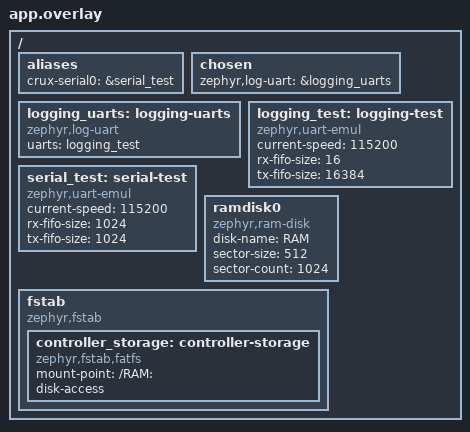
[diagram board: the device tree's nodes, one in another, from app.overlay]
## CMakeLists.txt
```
# SPDX-License-Identifier: Apache-2.0

# The base composition of the controller framework on native_sim, built as a product builds it:
# the framework is the Zephyr module of this repository, turned on by CONFIG_CRUX_CONTROLLER_FRAMEWORK
# in prj.conf. This file names no source and no include directory of this repository. It links the
# interface target of the module and calls the module's image function, which adds the route table
# and the packaged page of web management to the target app, as the base image does.

cmake_minimum_required(VERSION 3.20.0)
find_package(Zephyr REQUIRED HINTS $ENV{ZEPHYR_BASE})
project(controller_framework_base_native_sim LANGUAGES C)

if(NOT CONFIG_BOARD_NATIVE_SIM OR NOT CONFIG_FAKE_ENTROPY_NATIVE_SIM)
    message(FATAL_ERROR "This scenario is restricted to native_sim: its entropy source is a test source")
endif()
if(NOT CONFIG_CRUX_CONTROLLER_FRAMEWORK OR NOT CONFIG_CRUX_CONTROLLER_FRAMEWORK_MANAGEMENT
   OR NOT CONFIG_CRUX_CONTROLLER_FRAMEWORK_TIME_SYNC)
    message(FATAL_ERROR "The base scenario needs the framework with web management and time synchronisation")
endif()

target_sources(app PRIVATE src/test_base.c)
target_link_libraries(app PRIVATE controller::framework)
controller_framework_image()
```

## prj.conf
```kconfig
# The base composition of the controller framework on native_sim, as a product would build it:
# the framework comes from the module (zephyr/module.yml) and one Kconfig symbol, and the test
# reaches it through <controller/framework.h> only. The values below are those of the
# management scenario (tests/native_sim_mbed/management/prj.conf), with the framework, the SNTP
# library and a time server on the loopback address added. No SNTP server answers there, so the
# time synchronisation thread starts and its queries fail; the scenario checks that it started.
# The Crux serial console runs on an emulated UART of its own (app.overlay), into which the
# scenario types the first-account setup and a login.
CONFIG_CRUX_CONTROLLER_FRAMEWORK=y
CONFIG_SNTP=y
CONFIG_CRUX_CONTROLLER_TIME_SERVER="127.0.0.1"

# Health supervision as in the base image (app/conf/base.conf), in its production watchdog
# configuration (criterion 19): no task watchdog hardware fallback, no start without a watchdog, no
# fault injection. native_sim has no watchdog behind the alias crux-watchdog0 here, so the watchdog
# is not armed and the controller is degraded. There is no retained region either, so the boot
# counter lives in RAM. The stable period is longer than the scenario, so the counter is not cleared.
CONFIG_TASK_WDT=y
CONFIG_TASK_WDT_HW_FALLBACK=n
CONFIG_CRUX_REBOOT=y
CONFIG_CRUX_CONTROLLER_STABLE_PERIOD_S=3600

CONFIG_CRUX_SERIAL=y
CONFIG_CRUX_CLI=y
CONFIG_CRUX_CLI_CONSOLE=y
CONFIG_CRUX_CLI_CONSOLE_PRIORITY=11
CONFIG_UART_INTERRUPT_DRIVEN=y
CONFIG_UART_USE_RUNTIME_CONFIGURE=y

CONFIG_ZTEST=y
CONFIG_ZTEST_VERIFY_RUN_ALL=n
CONFIG_STD_C17=y
CONFIG_EMUL=y
CONFIG_UART_EMUL=y
CONFIG_IRQ_OFFLOAD=y
# The web adapter refuses the external libc of native_sim; the management scenario runs on picolibc.
CONFIG_PICOLIBC=y
# One thread of the test runs the start sequence (key generation, signing, the format of the RAM
# disk) and the TLS client. Not measured.
CONFIG_MAIN_STACK_SIZE=32768
CONFIG_ZTEST_STACK_SIZE=32768
CONFIG_HEAP_MEM_POOL_SIZE=32768

# The Mbed TLS profile of app/conf/management.conf, as a copy: this scenario has no Kconfig of the product,
# as in the management scenario. The heap is larger than the product's 120,000 bytes,
# because the TLS client of the test runs in the same process and takes up to one more connection
# and its own handshake. The product declares 120,000 bytes for three server connections of 34,912
# bytes, a handshake of 3,576 bytes and the other PSA users, and 180,000 leaves about 25,000 bytes
# over the worst concurrent case that this process can reach. A paper figure, not measured.
CONFIG_MBEDTLS=y
CONFIG_MBEDTLS_PSA_CRYPTO_C=y
CONFIG_PSA_CRYPTO_PROVIDER_MBEDTLS=y
CONFIG_MBEDTLS_ENABLE_HEAP=y
CONFIG_MBEDTLS_HEAP_SIZE=180000
CONFIG_MBEDTLS_SSL_IN_CONTENT_LEN=16384
CONFIG_MBEDTLS_SSL_OUT_CONTENT_LEN=16384
CONFIG_MBEDTLS_SSL_PROTO_TLS1_2=y
CONFIG_MBEDTLS_SSL_PROTO_TLS1_3=y
CONFIG_MBEDTLS_SSL_TLS1_3_KEY_EXCHANGE_MODE_EPHEMERAL_ENABLED=y
CONFIG_MBEDTLS_KEY_EXCHANGE_ECDHE_ECDSA_ENABLED=y
CONFIG_MBEDTLS_CIPHERSUITE_TLS_ECDHE_ECDSA_WITH_AES_128_GCM_SHA256=y
CONFIG_MBEDTLS_CIPHERSUITE_TLS1_3_AES_128_GCM_SHA256=y
CONFIG_PSA_WANT_ALG_SHA_256=y
CONFIG_PSA_WANT_ECC_SECP_R1_256=y
CONFIG_PSA_WANT_ALG_ECDSA=y
CONFIG_PSA_WANT_ALG_ECDH=y
CONFIG_PSA_WANT_ALG_GCM=y
CONFIG_PSA_WANT_KEY_TYPE_AES=y
CONFIG_PSA_WANT_ALG_HMAC=y
CONFIG_PSA_WANT_KEY_TYPE_HMAC=y
CONFIG_PSA_WANT_ALG_HKDF=y
CONFIG_PSA_WANT_ALG_PBKDF2_HMAC=y
CONFIG_PSA_WANT_ALG_TLS12_PRF=y
CONFIG_PSA_WANT_KEY_TYPE_ECC_PUBLIC_KEY=y
CONFIG_PSA_WANT_KEY_TYPE_ECC_KEY_PAIR_IMPORT=y
CONFIG_PSA_WANT_KEY_TYPE_ECC_KEY_PAIR_EXPORT=y
CONFIG_PSA_WANT_KEY_TYPE_ECC_KEY_PAIR_GENERATE=y
CONFIG_PSA_WANT_KEY_TYPE_ECC_KEY_PAIR_DERIVE=y
CONFIG_MBEDTLS_PK_WRITE_C=y
CONFIG_CRUX_PSA_THREADING=y

# The Crux services, as in app/conf/management.conf. The module selects Thread, Sync and Time for them.
CONFIG_CRUX_ACCESS=y
CONFIG_CRUX_CONFIG_SERVICE=y
CONFIG_CRUX_MGMT_STATUS=y
CONFIG_CRUX_TLS_CERTIFICATE=y
CONFIG_CRUX_WEB=y
CONFIG_CRUX_WEB_SESSION=y
CONFIG_CRUX_WEB_MANAGEMENT=y
CONFIG_CRUX_SYSTEM=y
CONFIG_CRUX_NETIF=y
CONFIG_WATCHDOG=y
CONFIG_HWINFO=y
CONFIG_REBOOT=y

# The listener binds the loopback address, and the TLS client of the test is in the same process. The
# listener opens on Zephyr's own thread, so the client retries its connect.
CONFIG_CRUX_WEB_PORT=443
CONFIG_CRUX_WEB_BIND_ADDRESS="127.0.0.1"
CONFIG_CRUX_WEB_BACKLOG=4
CONFIG_HTTP_SERVER_MAX_CLIENTS=3
CONFIG_HTTP_SERVER_STACK_SIZE=16384
CONFIG_CRUX_WEB_SESSION_WORKER_PRIORITY=11
CONFIG_CRUX_WEB_MANAGEMENT_WORKER_PRIORITY=11
CONFIG_CRUX_SECURITY_EVENT_DRAIN_PRIORITY=11

# The simulator's fake entropy source: test-only, so nothing made here is a secret.
CONFIG_ENTROPY_GENERATOR=y

# Crux File on a RAM disk with the simulator provider, and the formatting service that the zone
# uses when the blank disk does not mount.
CONFIG_FILE_SYSTEM=y
CONFIG_FILE_SYSTEM_MKFS=y
CONFIG_FAT_FILESYSTEM_ELM=y
CONFIG_FS_FATFS_LFN=y
CONFIG_FS_FATFS_LFN_MODE_STACK=y
CONFIG_FS_FATFS_MAX_LFN=127
CONFIG_FS_FATFS_MOUNT_MKFS=n
CONFIG_FS_FATFS_REENTRANT=y
CONFIG_FS_FATFS_NUM_FILES=6
CONFIG_DISK_DRIVERS=y
CONFIG_DISK_DRIVER_RAM=y
CONFIG_CRUX_FILE_FATFS_SIMULATOR=y

# The network: Zephyr's loopback interface, TCP and the TLS socket layer, with no host network.
CONFIG_NETWORKING=y
CONFIG_NET_IPV4=y
CONFIG_NET_IPV6=n
CONFIG_NET_TCP=y
CONFIG_NET_UDP=y
CONFIG_NET_SOCKETS=y
CONFIG_NET_DRIVERS=y
CONFIG_NET_LOOPBACK=y
CONFIG_NET_SOCKETS_SOCKOPT_TLS=y
CONFIG_TLS_CREDENTIALS=y
CONFIG_TLS_MAX_CREDENTIALS_NUMBER=4
CONFIG_NET_SOCKETS_TLS_MAX_CONTEXTS=6
CONFIG_ZVFS_OPEN_MAX=48
CONFIG_ZVFS_POLL_MAX=24
CONFIG_ZVFS_EVENTFD=y
CONFIG_NET_MAX_CONTEXTS=32
CONFIG_NET_MAX_CONN=32
CONFIG_NET_PKT_RX_COUNT=64
CONFIG_NET_PKT_TX_COUNT=64
CONFIG_NET_BUF_RX_COUNT=256
CONFIG_NET_BUF_TX_COUNT=256

# Crux Logging writes to an emulated UART, so that the test can read what it wrote.
CONFIG_CRUX_LOGGING=y
CONFIG_SERIAL=y
CONFIG_LOG=y
CONFIG_LOG_MODE_DEFERRED=y
CONFIG_LOG_MODE_OVERFLOW=n
CONFIG_LOG_BLOCK_IN_THREAD=n
CONFIG_LOG_PROCESS_THREAD=y
CONFIG_LOG_PROCESS_THREAD_STACK_SIZE=2048
CONFIG_LOG_PROCESS_THREAD_CUSTOM_PRIORITY=y
CONFIG_LOG_PROCESS_THREAD_PRIORITY=14
CONFIG_LOG_BUFFER_SIZE=8192
CONFIG_LOG_MAX_LEVEL=4
CONFIG_LOG_DEFAULT_LEVEL=0
CONFIG_LOG_RUNTIME_FILTERING=n
CONFIG_LOG_BACKEND_UART=y
CONFIG_LOG_BACKEND_NATIVE_POSIX=n
CONFIG_LOG_BACKEND_UART_ASYNC=n
CONFIG_LOG_PRINTK=n
CONFIG_SHELL_LOG_BACKEND=n
CONFIG_LOG_BACKEND_SHOW_LEVEL=y
CONFIG_LOG_BACKEND_CRLF_NONE=n
CONFIG_THREAD_MONITOR=y
CONFIG_THREAD_NAME=y
# An image with Crux management must not enable the Zephyr shell.
CONFIG_SHELL=n
```

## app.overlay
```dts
/* The devicetree of the management scenario (tests/native_sim_mbed/management/app.overlay).
 * Crux Logging writes to an emulated UART here, so that the test can read what it wrote. The RAM
 * disk and the fstab entry are the ones that boards/management.overlay declares for the board, with the
 * same names, because the composition zone looks up the entry controller_storage. The disk is
 * blank at every start: the zone formats it. The Crux serial console owns a second emulated UART
 * through the alias crux-serial0: the test types into its receive side and reads its transmit
 * side. */
/ {
    aliases { crux-serial0 = &serial_test; };
    chosen { zephyr,log-uart = &logging_uarts; };
    logging_uarts: logging-uarts {
        compatible = "zephyr,log-uart";
        uarts = <&logging_test>;
    };
    logging_test: logging-test {
        compatible = "zephyr,uart-emul";
        current-speed = <115200>;
        rx-fifo-size = <16>;
        tx-fifo-size = <16384>;
        status = "okay";
    };
    serial_test: serial-test {
        compatible = "zephyr,uart-emul";
        current-speed = <115200>;
        rx-fifo-size = <1024>;
        tx-fifo-size = <1024>;
        status = "okay";
    };

    ramdisk0 {
        compatible = "zephyr,ram-disk";
        disk-name = "RAM";
        sector-size = <512>;
        sector-count = <1024>;
    };

    fstab {
        compatible = "zephyr,fstab";
        controller_storage: controller-storage {
            compatible = "zephyr,fstab,fatfs";
            mount-point = "/RAM:";
            disk-access;
        };
    };
};
```

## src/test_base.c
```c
/* SPDX-License-Identifier: Apache-2.0 */

/* The base composition of the controller framework on native_sim, built as a product builds it:
 * the framework comes from the Zephyr module of this repository and the Kconfig symbol
 * CONFIG_CRUX_CONTROLLER_FRAMEWORK, the test calls the start function of
 * <controller/framework.h>, and the CMake file of this scenario names no source or include
 * directory of this repository. It runs the real Crux services, Zephyr's HTTP server with Mbed TLS
 * and the SNTP library over the loopback interface, and the Crux serial console on an emulated
 * UART, into which the test types as a person types at a terminal.
 *
 * One image runs the cases in order, because the start function runs once per program.
 *
 * Health supervision runs in its production watchdog configuration with no watchdog behind the
 * alias crux-watchdog0, so the watchdog is not armed and the controller is degraded (criterion 19,
 * base image part), and the scenario shows the start order of criterion 6: the reset cause read
 * once and cleared, the supervisor step before the step that mounts the volume, the captured copy
 * in the status service, and the end of startup supervision in step 12 with no application.
 *
 * What this scenario cannot show: anything on a board, the Ethernet interface, the board's UART for
 * the console, the RT1060 entropy source (the entropy here is the simulator's test source), a TLS
 * session or an HTTPS login (the management scenario shows those for the same start sequence), an
 * account that outlives a restart (the disk is a RAM disk), a synchronised clock (no SNTP server
 * answers on the loopback address), an armed watchdog, a retained region or a reset (the scenarios
 * recovery and no_watchdog show those), stack use or timing. */

#include <errno.h>
#include <stdbool.h>
#include <stddef.h>
#include <stdint.h>
#include <string.h>

#include <controller/framework.h>
#include <zephyr/device.h>
#include <zephyr/drivers/serial/uart_emul.h>
#include <zephyr/kernel.h>
#include <zephyr/logging/log_ctrl.h>
#include <zephyr/net/socket.h>
#include <zephyr/ztest.h>

#define LOG_UART DEVICE_DT_GET(DT_NODELABEL(logging_test))
#define CONSOLE_UART DEVICE_DT_GET(DT_NODELABEL(serial_test))
/* The listener opens on Zephyr's own thread, so the first connects can be refused. */
#define CONNECT_ATTEMPTS 40
#define CONNECT_RETRY_MS 100
/* The console polls in steps of this length, up to the number of attempts. */
#define CONSOLE_POLL_MS 10
#define CONSOLE_ATTEMPTS 1000

#define FIRST_USER "operator"
#define FIRST_PASSWORD "base image test password"
#define WRONG_PASSWORD "this is the wrong password"
/* The first eight bytes of each, which no prompt or reply of the console contains. */
#define FIRST_PASSWORD_START "base ima"
#define WRONG_PASSWORD_START "this is "

static char log_text[16384];
static size_t log_length;

/* Everything that Crux Logging wrote since the last call, appended to what was read before. */
static const char *drain_log(void)
{
    log_flush();
    log_length += uart_emul_get_tx_data(LOG_UART, (uint8_t *)log_text + log_length,
                                        sizeof log_text - 1u - log_length);
    log_text[log_length] = '\0';
    return log_text;
}

/* What the console has written and no expectation has consumed yet. */
static char console_text[8192];
static size_t console_length;

static void console_drain(void)
{
    uint8_t chunk[64];
    uint32_t got;

    while ((got = uart_emul_get_tx_data(CONSOLE_UART, chunk, sizeof chunk)) > 0u) {
        zassert_true(console_length + got < sizeof console_text, "the console wrote too much");
        memcpy(&console_text[console_length], chunk, got);
        console_length += got;
        console_text[console_length] = '\0';
        /* A password is read without echo: neither a whole one nor its first bytes come back. */
        zassert_is_null(strstr(console_text, FIRST_PASSWORD_START), "a password was echoed");
        zassert_is_null(strstr(console_text, WRONG_PASSWORD_START), "a password was echoed");
    }
}

/* Wait for the console to write text, then drop everything up to and including it. With first,
 * nothing may come before it. */
static void console_expect(const char *text, bool first)
{
    const size_t length = strlen(text);

    for (int attempt = 0; attempt < CONSOLE_ATTEMPTS; attempt++) {
        console_drain();
        const char *found = strstr(console_text, text);

        if (first && console_length >= length) {
            zassert_equal(strncmp(console_text, text, length), 0, "first output: %s", console_text);
        }
        if (found != NULL) {
            const size_t consumed = (size_t)(found - console_text) + length;

            memmove(console_text, &console_text[consumed], console_length - consumed + 1u);
            console_length -= consumed;
            return;
        }
        k_msleep(CONSOLE_POLL_MS);
    }
    zassert_unreachable("the console did not write \"%s\"; it wrote \"%s\"", text, console_text);
}

/* Type a line as a terminal does: the bytes and a carriage return. */
static void console_type(const char *text)
{
    char line[96];
    const size_t length = strlen(text);

    zassert_true(length + 1u < sizeof line);
    memcpy(line, text, length);
    line[length] = '\r';
    zassert_equal(uart_emul_put_rx_data(CONSOLE_UART, (const uint8_t *)line, length + 1u),
                  length + 1u);
}

ZTEST_SUITE(base, NULL, NULL, NULL, NULL, NULL);

ZTEST(base, test_01_start_runs_every_phase)
{
    zassert_equal(controller_framework_start(NULL), CONTROLLER_FRAMEWORK_OK);
    const char *log = drain_log();

    zassert_not_null(strstr(log, "phase clock ok"), "%s", log);
    zassert_not_null(strstr(log, "phase supervisor ok"), "%s", log);
    zassert_not_null(strstr(log, "phase storage access ok"), "%s", log);
    zassert_not_null(strstr(log, "phase web management ok"), "%s", log);
    zassert_not_null(strstr(log, "phase command line ok"), "%s", log);
    zassert_not_null(strstr(log, "phase time synchronisation ok"), "%s", log);
    zassert_not_null(strstr(log, "phase application ok"), "%s", log);
    /* With no application, the application's own steps (init and the start prerequisites) are
     * left out and not counted. */
    zassert_not_null(strstr(log, "phase app init left out: no application"), "%s", log);
    zassert_not_null(strstr(log, "phase start prerequisites left out: no application"), "%s", log);
    zassert_not_null(strstr(log, "startup done phases=7 failed=0"), "%s", log);
}

ZTEST(base, test_02_phases_run_in_order)
{
    const char *log = drain_log();
    const char *clock = strstr(log, "phase clock ok");
    const char *supervisor = strstr(log, "phase supervisor ok");
    const char *storage = strstr(log, "phase storage access ok");
    const char *web = strstr(log, "phase web management ok");
    const char *cli = strstr(log, "phase command line ok");
    const char *time = strstr(log, "phase time synchronisation ok");
    const char *application = strstr(log, "phase application ok");

    zassert_true(clock != NULL && supervisor != NULL && storage != NULL && web != NULL &&
                     cli != NULL && time != NULL && application != NULL,
                 "%s", log);
    zassert_true(clock < supervisor && supervisor < storage && storage < web && web < cli &&
                     cli < time && time < application,
                 "%s", log);
    zassert_not_null(strstr(log, "https management started on 127.0.0.1 port 443"), "%s", log);
    zassert_not_null(strstr(log, "serial command line started on crux-serial0"), "%s", log);
}

ZTEST(base, test_03_a_second_start_is_refused)
{
    zassert_equal(controller_framework_start(NULL), CONTROLLER_FRAMEWORK_ERR_ALREADY_STARTED);
}

ZTEST(base, test_04_the_listener_accepts_a_connection)
{
    struct net_sockaddr_in address = {
        .sin_family = NET_AF_INET,
        .sin_port = net_htons(443),
    };
    int last_errno = 0;
    bool connected = false;

    zassert_equal(zsock_inet_pton(NET_AF_INET, "127.0.0.1", &address.sin_addr), 1);
    for (int attempt = 0; attempt < CONNECT_ATTEMPTS && !connected; attempt++) {
        const int sock = zsock_socket(NET_AF_INET, NET_SOCK_STREAM, NET_IPPROTO_TCP);

        zassert_true(sock >= 0, "no socket (errno %d)", errno);
        if (zsock_connect(sock, (const struct net_sockaddr *)&address, sizeof address) == 0) {
            connected = true;
        } else {
            last_errno = errno;
            k_msleep(CONNECT_RETRY_MS);
        }
        (void)zsock_close(sock);
    }
    zassert_true(connected, "no connection to the listener (errno %d)", last_errno);
}

/* A new image has no account: the console prints its login prompt and nothing before it, and a
 * login is refused. */
ZTEST(base, test_05_the_console_prompts_first_and_refuses_a_login_without_accounts)
{
    zassert_true(device_is_ready(CONSOLE_UART));
    console_expect("login: ", true);
    console_type(FIRST_USER);
    console_expect("password: ", false);
    console_type(WRONG_PASSWORD);
    console_expect("login failed", false);
    console_expect("login: ", false);
}

/* The first account is made over the serial command line, from typed input. */
ZTEST(base, test_06_setup_creates_the_first_account)
{
    console_type("!setup");
    console_expect("new user: ", false);
    console_type(FIRST_USER);
    console_expect("password: ", false);
    console_type(FIRST_PASSWORD);
    console_expect("repeat: ", false);
    console_type(FIRST_PASSWORD);
    console_expect("account created", false);
    console_expect("login: ", false);
}

/* Setup is refused once an account exists. */
ZTEST(base, test_07_a_second_setup_is_refused)
{
    console_type("!setup");
    console_expect("new user: ", false);
    console_type("second");
    console_expect("password: ", false);
    console_type(FIRST_PASSWORD);
    console_expect("repeat: ", false);
    console_type(FIRST_PASSWORD);
    console_expect("setup not available", false);
    console_expect("login: ", false);
}

/* The first account logs in, runs a command and logs out. */
ZTEST(base, test_08_the_first_account_logs_in_and_runs_a_command)
{
    console_type(FIRST_USER);
    console_expect("password: ", false);
    console_type(FIRST_PASSWORD);
    console_expect("> ", false);
    console_type("help");
    console_expect("logout", false);
    console_expect("> ", false);
    console_type("logout");
    console_expect("login: ", false);
}

/* Criterion 6, base image part: the reset cause is read once in step 1 and the flags cleared after
 * the capture; the supervisor step, which arms the watchdog, ends before the step that mounts the
 * volume begins; and startup supervision ends in step 12 with no application. This scenario has no
 * watchdog; the scenario recovery (testcase.yaml) shows "watchdog armed" before the management step
 * with the simulated watchdog. */
ZTEST(base, test_09_the_start_order_of_supervision)
{
    const char *log = drain_log();
    static const char capture_line[] = "reset cause=0x001 supported=0x005 captured, flags cleared";
    const char *capture = strstr(log, capture_line);
    const char *boot = strstr(log, "boot class=power counter=0 threshold=3 safe mode=no "
                                   "no retained region");
    const char *watchdog = strstr(log, "watchdog not armed");
    const char *supervisor = strstr(log, "phase supervisor ok");
    /* The step "storage access" mounts the volume (startup step 3). */
    const char *mount = strstr(log, "phase storage access ok");
    const char *web = strstr(log, "https management started");
    const char *ended = strstr(log, "startup supervision ended in step 12 with no application");

    zassert_true(capture != NULL && boot != NULL && watchdog != NULL && supervisor != NULL &&
                     mount != NULL && web != NULL && ended != NULL,
                 "%s", log);
    zassert_true(capture < boot && boot < watchdog && watchdog < supervisor && supervisor < mount &&
                     mount < web && web < ended,
                 "%s", log);
    /* Read once: no second capture line after the first. */
    zassert_is_null(strstr(capture + sizeof capture_line - 1u, "captured, flags"), "%s", log);
}

/* Criterion 19, base image part: with the production watchdog configuration and no watchdog, the
 * controller is degraded once startup supervision has ended. */
ZTEST(base, test_10_a_watchdog_that_is_not_armed_degrades_the_controller)
{
    const char *log = NULL;

    for (int attempt = 0; attempt < 50; attempt++) {
        k_msleep(100);
        log = drain_log();
        if (strstr(log, "controller state=degraded") != NULL) {
            break;
        }
    }
    zassert_not_null(strstr(log, "controller state=degraded"), "%s", log);
    zassert_is_null(strstr(log, "controller state=operational"), "%s", log);
}

/* The status service shows the copy of the reset cause that step 1 captured (POR, although the
 * flags were cleared after the capture) and the framework's items, through the status command of
 * the serial command line, the certificate made at this boot included. */
ZTEST(base, test_11_the_status_command_shows_the_captured_cause_and_the_framework_items)
{
    console_type(FIRST_USER);
    console_expect("password: ", false);
    console_type(FIRST_PASSWORD);
    console_expect("> ", false);
    console_type("status");
    console_expect("{\"name\":\"reset.causes\",\"status\":\"ok\",\"type\":\"u32\",\"value\":1}",
                   false);
    console_expect("{\"name\":\"controller.state\",\"status\":\"ok\",\"type\":\"text\","
                   "\"value\":\"degraded\"}",
                   false);
    console_expect("{\"name\":\"controller.application\",\"status\":\"ok\",\"type\":\"text\","
                   "\"value\":\"absent\"}",
                   false);
    console_expect("{\"name\":\"controller.safe_mode\",\"status\":\"ok\",\"type\":\"bool\","
                   "\"value\":false}",
                   false);
    console_expect("{\"name\":\"controller.boot_counter\",\"status\":\"ok\",\"type\":\"u32\","
                   "\"value\":0}",
                   false);
    console_expect("{\"name\":\"controller.boot\",\"status\":\"ok\",\"type\":\"text\","
                   "\"value\":\"power\"}",
                   false);
    console_expect("{\"name\":\"controller.watchdog\",\"status\":\"ok\",\"type\":\"text\","
                   "\"value\":\"not-armed\"}",
                   false);
    console_expect("{\"name\":\"controller.last_fault\",\"status\":\"ok\",\"type\":\"text\","
                   "\"value\":\"none\"}",
                   false);
    console_expect("{\"name\":\"controller.stack_min\",\"status\":\"ok\",\"type\":\"text\"", false);
    /* The blank disk holds no device identity, so Crux made the key and a self-signed certificate
     * in this boot, and the status service says so (specification section 5.5, interim state). */
    console_expect("{\"name\":\"controller.certificate\",\"status\":\"ok\",\"type\":\"text\","
                   "\"value\":\"made at boot\"}",
                   false);
    console_expect("> ", false);
    console_type("logout");
    console_expect("login: ", false);
}
```
